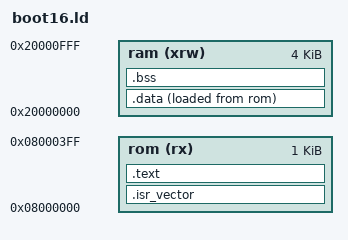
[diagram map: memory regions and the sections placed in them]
ENTRY(Reset_Handler)

_estack = ORIGIN(ram) + LENGTH(ram);

MEMORY {
  rom (rx)  : ORIGIN = 0x08000000, LENGTH = 1K
  ram (xrw) : ORIGIN = 0x20000000, LENGTH = 4K
}

SECTIONS {
  .isr_vector : {
    . = ALIGN(4);
    KEEP(*(.isr_vector))
    . = ALIGN(4);
  } >rom

  .text : {
    . = ALIGN(4);
    *(.text)
    *(.text*)
    *(.rodata)
    *(.rodata*)
    . = ALIGN(4);
  } >rom

  _sidata = LOADADDR(.data);

  .data : {
    . = ALIGN(4);
    _sdata = .;
    *(.data)
    *(.data*)
    *(.RamFunc)
    *(.RamFunc*)
    . = ALIGN(4);
    _edata = .;
  } >ram AT >rom

  .bss : {
    . = ALIGN(4);
    _sbss = .;
    *(.bss)
    *(.bss*)
    *(COMMON)
    . = ALIGN(4);
    _ebss = .;
  } >ram

  /DISCARD/ : {
    *(.init)
    *(.fini)
    libc.a ( * )
    libm.a ( * )
    libgcc.a ( * )
  }

  .ARM.attributes 0 : { *(.ARM.attributes) }
}
